# STM32F103 register map
File version: 1.1
CPU: CM3 r1p1, little endian, no MPU, no FPU, 4 interrupt priority bits
Registers are 32-bit, read-write, reset 0x0 unless marked. A register's access mark holds for its fields unless they carry their own. Offsets are from the block's base; [hi:lo] are bit positions; {n}, {i} and the like mark numbered series.

## RTC — Real time clock
Base 0x40002800
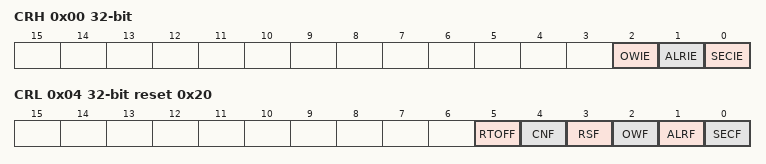
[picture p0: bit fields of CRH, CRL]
0x00 CRH — RTC Control Register High
  [2] OWIE — Overflow interrupt Enable
    0=Disabled (Overflow interrupt is masked); 1=Enabled (Overflow interrupt is enabled)
  [1] ALRIE — Alarm interrupt Enable
    0=Disabled (Alarm interrupt is masked); 1=Enabled (Alarm interrupt is enabled)
  [0] SECIE — Second interrupt Enable
    0=Disabled (Second interrupt is masked); 1=Enabled (Second interrupt is enabled)
0x04 CRL access per field reset 0x20 — RTC Control Register Low
  [5] RTOFF ro — RTC operation OFF
    0=Enabled (Last write operation on RTC registers is still ongoing); 1=Disabled (Last write operation on RTC registers terminated)
  [4] CNF rw — Configuration Flag
    0=Exit configuration mode (start update of RTC registers); 1=Enter configuration mode
  [3] RSF rw write-0-clears — Registers Synchronized Flag
    on read: 0=NotSynchronized (Registers not yet synchronized); 1=Synchronized (Registers synchronized) | on write: 0=Clear flag
  [2] OWF rw write-0-clears — Overflow Flag
    on read: 0=NoOverflow (Overflow not detected); 1=Overflow (32-bit programmable counter overflow occurred) | on write: 0=Clear flag
  [1] ALRF rw write-0-clears — Alarm Flag
    on read: 0=NoAlarm (Alarm not detected); 1=Alarm detected | on write: 0=Clear flag
  [0] SECF rw write-0-clears — Second Flag
    on read: 0=NoPrescalerOverflow (Second flag condition not met); 1=PrescalerOverflow (Second flag condition met) | on write: 0=Clear flag
0x08 PRLH wo — RTC Prescaler Load Register High
  [3:0] PRLH
0x0C PRLL wo reset 0x8000 — RTC Prescaler Load Register Low
  [15:0] PRLL — RTC Prescaler Divider Register Low
0x10 DIVH ro — RTC Prescaler Divider Register High
  [3:0] DIVH — RTC prescaler divider register high
0x14 DIVL ro reset 0x8000 — RTC Prescaler Divider Register Low
  [15:0] DIVL — RTC prescaler divider register Low
0x18 CNTH — RTC Counter Register High
  [15:0] CNTH — RTC counter register high
0x1C CNTL — RTC Counter Register Low
  [15:0] CNTL — RTC counter register Low
0x20 ALRH wo reset 0xFFFF — RTC Alarm Register High
  [15:0] ALRH — RTC alarm register high
0x24 ALRL wo reset 0xFFFF — RTC Alarm Register Low
  [15:0] ALRL — RTC alarm register low

## BKP — Backup registers
Base 0x40006C04
0x00 DR{i} (i=1..10; step 0x4) — Backup data register (BKP_DR)
  [15:0] D — Backup data
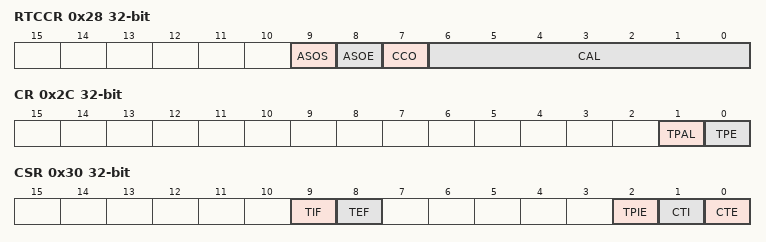
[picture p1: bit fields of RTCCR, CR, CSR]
0x28 RTCCR — RTC clock calibration register (BKP_RTCCR)
  [9] ASOS — Alarm or second output selection
    0=Alarm (RTC Alarm pulse output selected); 1=Second (RTC Second pulse output selected)
  [8] ASOE — Alarm or second output enable
    0=Disabled; 1=Enabled (Setting this bit outputs either the RTC Alarm pulse signal or the Second pulse signal on the TAMPER pin depending on the ASOS bit)
  [7] CCO — Calibration Clock Output
  [6:0] CAL range 0..121 — Calibration value
0x2C CR — Backup control register (BKP_CR)
  [1] TPAL — Tamper pin active level
    0=High (A high level on the TAMPER pin resets all data backup registers (if TPE bit is set)); 1=Low (A low level on the TAMPER pin resets all data backup registers (if TPE bit is set))
  [0] TPE — Tamper pin enable
    0=General (The TAMPER pin is free for general purpose I/O); 1=Alternate (Tamper alternate I/O function is activated)
0x30 CSR access per field — BKP_CSR control/status register (BKP_CSR)
  [9] TIF ro — Tamper Interrupt Flag
  [8] TEF ro — Tamper Event Flag
  [2] TPIE rw — Tamper Pin interrupt enable
    0=Disabled (Tamper interrupt disabled); 1=Enabled (Tamper interrupt enabled (the TPE bit must also be set in the BKP_CR register)
  [1] CTI wo — Clear Tamper Interrupt
    1=Clear the Tamper interrupt and the TIF Tamper interrupt flag
  [0] CTE wo — Clear Tamper event
    1=Reset the TEF Tamper event flag (and the Tamper detector)
{0x10+4i} BKP_DR{i} (i=11..42) — Backup data register (BKP_DR)
  [15:0] D — Backup data
